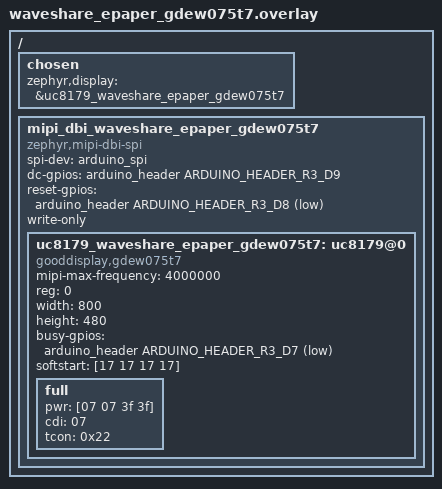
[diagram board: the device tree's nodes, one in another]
/*
 * Copyright (c) 2020, PHYTEC Messtechnik GmbH
 *
 * SPDX-License-Identifier: Apache-2.0
 */

#include "waveshare_epaper_common.dtsi"
#include <zephyr/dt-bindings/gpio/arduino-header-r3.h>

/ {
	chosen {
		zephyr,display = &uc8179_waveshare_epaper_gdew075t7;
	};

	mipi_dbi_waveshare_epaper_gdew075t7 {
		compatible = "zephyr,mipi-dbi-spi";
		spi-dev = <&arduino_spi>;
		dc-gpios = <&arduino_header ARDUINO_HEADER_R3_D9 GPIO_ACTIVE_HIGH>;
		reset-gpios = <&arduino_header ARDUINO_HEADER_R3_D8 GPIO_ACTIVE_LOW>;
		write-only;
		#address-cells = <1>;
		#size-cells = <0>;

		uc8179_waveshare_epaper_gdew075t7: uc8179@0 {
			compatible = "gooddisplay,gdew075t7", "ultrachip,uc8179";
			mipi-max-frequency = <4000000>;
			reg = <0>;
			width = <800>;
			height = <480>;
			busy-gpios = <&arduino_header ARDUINO_HEADER_R3_D7 GPIO_ACTIVE_LOW>;

			softstart = [17 17 17 17];

			full {
				pwr = [07 07 3f 3f];
				cdi = <07>;
				tcon = <0x22>;
			};
		};
	};
};
